# NPCX490M register map
File version: 1.0
Registers are 8-bit, read-write, reset 0x0 unless marked. A register's access mark holds for its fields unless they carry their own. Offsets are from the block's base; [hi:lo] are bit positions; {n}, {i} and the like mark numbered series.

## PMC
Base 0x4000D000
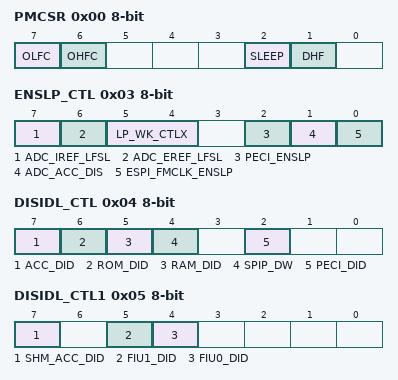
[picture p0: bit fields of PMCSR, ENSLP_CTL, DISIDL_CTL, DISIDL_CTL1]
0x00 PMCSR — Power Management Controller Status Register (PMCSR)
  [7] OLFC — Oscillating Low-Frequency Clock
  [6] OHFC — Oscillating High-Frequency Clock
  [2] SLEEP — Sleep Power States
  [1] DHF — Disable High-Frequency Oscillator
0x03 ENSLP_CTL — Enable in Sleep Control Register (ENSLP_CTL)
  [7] ADC_IREF_LFSL — ADC_IREF Low-Frequency Clock Select
  [6] ADC_EREF_LFSL — ADC_EREF Low-Frequency Clock Select
  [5:4] LP_WK_CTLX — Low-Power Wake-Up Control
  [2] PECI_ENSLP — PECI Enable in Sleep
  [1] ADC_ACC_DIS — ADC Access is Disabled
  [0] ESPI_FMCLK_ENSLP — eSPI_SIF FMCLK Enable in Sleep
0x04 DISIDL_CTL — Disable in Idle Control Register (DISIDL_CTL)
  [7] ACC_DID — Access Disable in Idle
  [6] ROM_DID — ROM Disable in Idle
  [5] RAM_DID — RAM Disable in Idle
  [4] SPIP_DW — SPI Peripheral Disable in Idle
  [2] PECI_DID — PECI Disable in Idle
0x05 DISIDL_CTL1 — Disable in Idle Control 1 Register (DISIDL_CTL1)
  [7] SHM_ACC_DID — SHM Access Disable in Idle
  [5] FIU1_DID — FIU1 Disable in Idle
  [4] FIU0_DID — FIU0 Disable in Idle
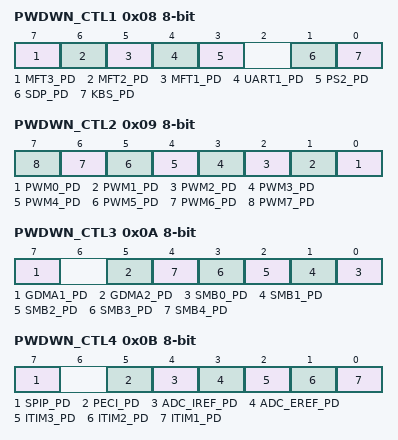
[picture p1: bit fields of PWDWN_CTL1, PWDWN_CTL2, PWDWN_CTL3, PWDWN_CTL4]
0x08 PWDWN_CTL1 — Power-Down Control 1 Register (PWDWN_CTL1)
  [7] MFT3_PD — MFT16-3 Power-Down
  [6] MFT2_PD — MFT16-2 Power-Down
  [5] MFT1_PD — MFT16-1 Power-Down
  [4] UART1_PD — CR_UART1 Power-Down
  [3] PS2_PD — PS/2 Power-Down
  [1] SDP_PD — SDP Power-Down
  [0] KBS_PD — Keyboard Scan Power-Down
0x09 PWDWN_CTL2 — Power-Down Control 2 Register (PWDWN_CTL2)
  [n] PWM{n}_PD (n=0..7) — PWM{n} Power-Down
0x0A PWDWN_CTL3 — Power-Down Control 3 Register (PWDWN_CTL3)
  [7] GDMA1_PD — GDMA1 Power-Down
  [5] GDMA2_PD — GDMA2 Power-Down
  [n] SMB{n}_PD (n=0..4) — SMB{n} Power-Down
0x0B PWDWN_CTL4 — Power-Down Control 4 Register (PWDWN_CTL4)
  [7] SPIP_PD — SPI Peripheral Power-Down
  [5] PECI_PD — PECI Power-Down
  [4] ADC_IREF_PD — ADC_IREF Power-Down
  [3] ADC_EREF_PD — ADC_EREF Power-Down
  [2] ITIM3_PD — ITIM32-3 Power-Down
  [1] ITIM2_PD — ITIM32-2 Power-Down
  [0] ITIM1_PD — ITIM32-1 Power-Down
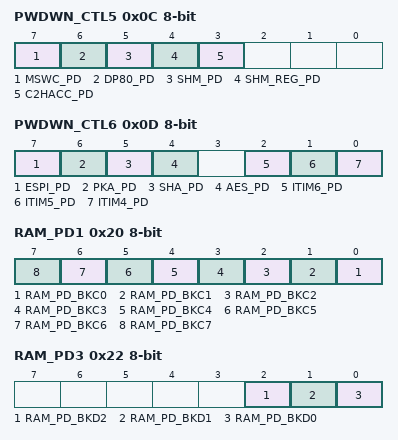
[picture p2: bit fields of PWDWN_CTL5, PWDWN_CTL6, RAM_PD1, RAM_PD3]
0x0C PWDWN_CTL5 — Power-Down Control 5 Register (PWDWN_CTL5)
  [7] MSWC_PD — MSWC Power-Down
  [6] DP80_PD — Debug Port 80 Power-Down
  [5] SHM_PD — SHM Power-Down
  [4] SHM_REG_PD — SHM Registers Power-Down
  [3] C2HACC_PD — Core-to-Host Module Power-Down
0x0D PWDWN_CTL6 — Power-Down Control 6 Register (PWDWN_CTL6)
  [7] ESPI_PD — eSPI_SIF Power-Down
  [6] PKA_PD — PKA Power-Down
  [5] SHA_PD — SHA Power-Down
  [4] AES_PD — AES Power-Down
  [2] ITIM6_PD — ITIM32-6 Power-Down
  [1] ITIM5_PD — ITIM32-5 Power-Down
  [0] ITIM4_PD — ITIM32-4 Power-Down
0x20 RAM_PD1 — RAM Power-Down Control 1 Register (RAM_PD1)
  [n] RAM_PD_BKC{n} (n=0..7) — RAM Power-Down Code Block {n}
0x22 RAM_PD3 — RAM Power-Down Control 3 Register (RAM_PD3)
  [2] RAM_PD_BKD2 — RAM Power-Down Data Block 2
  [1] RAM_PD_BKD1 — RAM Power-Down Data Block 1
  [0] RAM_PD_BKD0 — RAM Power-Down Data Block 0
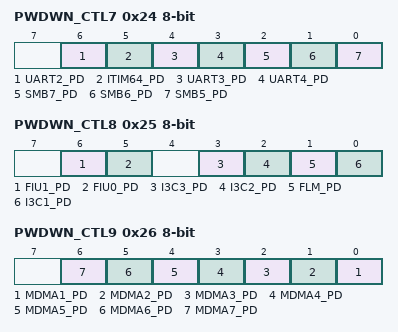
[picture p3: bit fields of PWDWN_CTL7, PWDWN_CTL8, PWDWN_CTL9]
0x24 PWDWN_CTL7 — Power-Down Control 7 Register (PWDWN_CTL7)
  [6] UART2_PD — CR_UART2 Power-Down
  [5] ITIM64_PD — ITIM64 Power-Down
  [4] UART3_PD — CR_UART3 Power-Down
  [3] UART4_PD — CR_UART4 Power-Down
  [2] SMB7_PD — SMB7 Power-Down
  [1] SMB6_PD — SMB6 Power-Down
  [0] SMB5_PD — SMB5 Power-Down
0x25 PWDWN_CTL8 — Power-Down Control 8 Register (PWDWN_CTL8)
  [6] FIU1_PD — FIU1 Power-Down
  [5] FIU0_PD — FIU0 Power-Down
  [3] I3C3_PD — I3C3 Power-Down
  [2] I3C2_PD — I3C2 Power-Down
  [1] FLM_PD — FLM Power-Down
  [0] I3C1_PD — I3C1 Power-Down
0x26 PWDWN_CTL9 — Power-Down Control 9 Register (PWDWN_CTL9)
  [n-1] MDMA{n}_PD (n=1..7) — MDMA{n} Power-Down

## PS2
Base 0x400B1000
0x00 PSDAT — PS/2 Data Register (PSDAT)
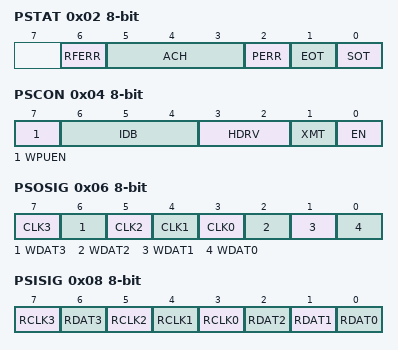
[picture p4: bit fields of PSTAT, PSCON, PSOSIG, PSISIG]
0x02 PSTAT — PS/2 Status Register (PSTAT)
  [6] RFERR — Receive Frame Error
  [5:3] ACH — Active Channel
  [2] PERR — Parity Error
  [1] EOT — End Of Transaction
  [0] SOT — Start Of Transaction
0x04 PSCON — PS/2 Control Register (PSCON)
  [7] WPUEN — Weak Pull-Up Enable
  [6:4] IDB — Input Debounce
  [3:2] HDRV — High Drive
  [1] XMT — Transmit Enable
  [0] EN — Shift Mechanism Enable
0x06 PSOSIG — PS/2 Output Signal Register (PSOSIG)
  [7] CLK3 — Enable Channel 3
  [6] WDAT3 — Write Data Signal Channel 3
  [5] CLK2 — Enable Channel 2
  [4] CLK1 — Enable Channel 1
  [3] CLK0 — Enable Channel 0
  [2] WDAT2 — Write Data Signal Channel 2
  [1] WDAT1 — Write Data Signal Channel 1
  [0] WDAT0 — Write Data Signal Channel 0
0x08 PSISIG — PS/2 Input Signal Register (PSISIG)
  [7] RCLK3 — Read Clock Signal Channel 3
  [6] RDAT3 — Read Data Signal Channel 3
  [5] RCLK2 — Read Clock Signal Channel 2
  [4] RCLK1 — Read Clock Signal Channel 1
  [3] RCLK0 — Read Clock Signal Channel 0
  [2] RDAT2 — Read Data Signal Channel 2
  [1] RDAT1 — Read Data Signal Channel 1
  [0] RDAT0 — Read Data Signal Channel 0
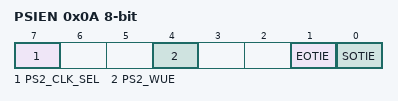
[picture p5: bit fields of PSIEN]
0x0A PSIEN — PS/2 Interrupt Enable Register (PSIEN)
  [7] PS2_CLK_SEL — PS/2 Interface Clock Select
  [4] PS2_WUE — PS/2 Wake-Up Enable
  [1] EOTIE — End Of Transaction Interrupt Enable
  [0] SOTIE — Start Of Transaction Interrupt Enable
